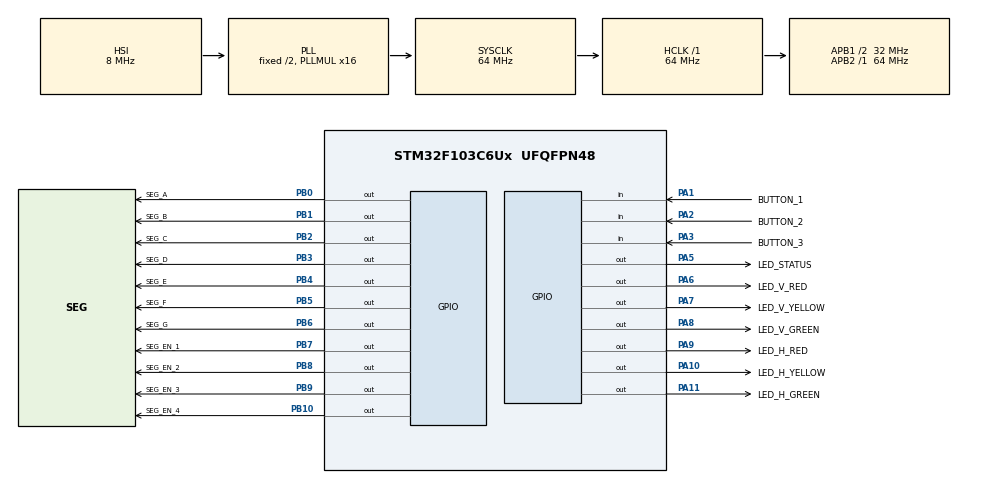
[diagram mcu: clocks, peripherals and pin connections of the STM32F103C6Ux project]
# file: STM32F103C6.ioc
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Mcu.Family=STM32F1
Mcu.Name=STM32F103C6Ux
Mcu.Package=UFQFPN48
NVIC.PriorityGroup=NVIC_PRIORITYGROUP_4
NVIC.TIM2_IRQn=true\:0\:0\:false\:false\:true\:true\:true\:true
PA1.GPIO_Label=BUTTON_1
PA1.GPIO_PuPd=GPIO_PULLUP
PA1.Signal=GPIO_Input
PA10.GPIO_Label=LED_H_YELLOW
PA10.Signal=GPIO_Output
PA11.GPIO_Label=LED_H_GREEN
PA11.Signal=GPIO_Output
PA2.GPIO_Label=BUTTON_2
PA2.GPIO_PuPd=GPIO_PULLUP
PA2.Signal=GPIO_Input
PA3.GPIO_Label=BUTTON_3
PA3.GPIO_PuPd=GPIO_PULLUP
PA3.Signal=GPIO_Input
PA5.GPIO_Label=LED_STATUS
PA5.Signal=GPIO_Output
PA6.GPIO_Label=LED_V_RED
PA6.Signal=GPIO_Output
PA7.GPIO_Label=LED_V_YELLOW
PA7.Signal=GPIO_Output
PA8.GPIO_Label=LED_V_GREEN
PA8.Signal=GPIO_Output
PA9.GPIO_Label=LED_H_RED
PA9.Signal=GPIO_Output
PB0.GPIO_Label=SEG_A
PB0.Signal=GPIO_Output
PB1.GPIO_Label=SEG_B
PB1.Signal=GPIO_Output
PB10.GPIO_Label=SEG_EN_4
PB10.Signal=GPIO_Output
PB2.GPIO_Label=SEG_C
PB2.Signal=GPIO_Output
PB3.GPIO_Label=SEG_D
PB3.Signal=GPIO_Output
PB4.GPIO_Label=SEG_E
PB4.Signal=GPIO_Output
PB5.GPIO_Label=SEG_F
PB5.Signal=GPIO_Output
PB6.GPIO_Label=SEG_G
PB6.Signal=GPIO_Output
PB7.GPIO_Label=SEG_EN_1
PB7.Signal=GPIO_Output
PB8.GPIO_Label=SEG_EN_2
PB8.Signal=GPIO_Output
PB9.GPIO_Label=SEG_EN_3
PB9.Signal=GPIO_Output
ProjectManager.HeapSize=0x200
ProjectManager.StackSize=0x400
ProjectManager.TargetToolchain=Makefile
RCC.AHBFreq_Value=64000000
RCC.APB1CLKDivider=RCC_HCLK_DIV2
RCC.APB1Freq_Value=32000000
RCC.APB1TimFreq_Value=64000000
RCC.APB2Freq_Value=64000000
RCC.APB2TimFreq_Value=64000000
RCC.HCLKFreq_Value=64000000
RCC.PLLMUL=RCC_PLL_MUL16
RCC.SYSCLKFreq_VALUE=64000000
RCC.SYSCLKSource=RCC_SYSCLKSOURCE_PLLCLK
RCC.USBFreq_Value=64000000
TIM2.Period=9
TIM2.Prescaler=6399
VP_SYS_VS_ND.Mode=No_Debug
VP_TIM2_VS_ClockSourceINT.Mode=Internal
board=custom

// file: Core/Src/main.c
/* USER CODE BEGIN Header */
/**
 ******************************************************************************
 * @file           : main.c
 * @brief          : Main program body
 ******************************************************************************
 * @attention
 *
 * Copyright (c) 2023 STMicroelectronics.
 * All rights reserved.
 *
 * This software is licensed under terms that can be found in the LICENSE file
 * in the root directory of this software component.
 * If no LICENSE file comes with this software, it is provided AS-IS.
 *
 ******************************************************************************
 */
/* USER CODE END Header */
#include "main.h"
#include "tim.h"
#include "gpio.h"

/* USER CODE BEGIN Includes */
#include "traffic_sim.h"
/* USER CODE END Includes */

void SystemClock_Config(void);

int main(void)
{

  /* MCU Configuration--------------------------------------------------------*/

  /* Reset of all peripherals, Initializes the Flash interface and the Systick. */
  HAL_Init();

  /* Configure the system clock */
  SystemClock_Config();

  /* Initialize all configured peripherals */
  MX_GPIO_Init();
  MX_TIM2_Init();
  /* USER CODE BEGIN 2 */
  traffic_sim_t ts;
  traffic_sim_init(&ts);
  /* USER CODE END 2 */

  /* Infinite loop */
  /* USER CODE BEGIN WHILE */
  while (1) {
    traffic_sim_main(&ts);
    /* USER CODE END WHILE */

  }
}

void SystemClock_Config(void)
{
  RCC_OscInitTypeDef RCC_OscInitStruct = {0};
  RCC_ClkInitTypeDef RCC_ClkInitStruct = {0};

  /** Initializes the RCC Oscillators according to the specified parameters
  * in the RCC_OscInitTypeDef structure.
  */
  RCC_OscInitStruct.OscillatorType = RCC_OSCILLATORTYPE_HSI;
  RCC_OscInitStruct.HSIState = RCC_HSI_ON;
  RCC_OscInitStruct.HSICalibrationValue = RCC_HSICALIBRATION_DEFAULT;
  RCC_OscInitStruct.PLL.PLLState = RCC_PLL_ON;
  RCC_OscInitStruct.PLL.PLLSource = RCC_PLLSOURCE_HSI_DIV2;
  RCC_OscInitStruct.PLL.PLLMUL = RCC_PLL_MUL16;
  if (HAL_RCC_OscConfig(&RCC_OscInitStruct) != HAL_OK)
  {
    Error_Handler();
  }

  /** Initializes the CPU, AHB and APB buses clocks
  */
  RCC_ClkInitStruct.ClockType = RCC_CLOCKTYPE_HCLK|RCC_CLOCKTYPE_SYSCLK
                              |RCC_CLOCKTYPE_PCLK1|RCC_CLOCKTYPE_PCLK2;
  RCC_ClkInitStruct.SYSCLKSource = RCC_SYSCLKSOURCE_PLLCLK;
  RCC_ClkInitStruct.AHBCLKDivider = RCC_SYSCLK_DIV1;
  RCC_ClkInitStruct.APB1CLKDivider = RCC_HCLK_DIV2;
  RCC_ClkInitStruct.APB2CLKDivider = RCC_HCLK_DIV1;

  if (HAL_RCC_ClockConfig(&RCC_ClkInitStruct, FLASH_LATENCY_2) != HAL_OK)
  {
    Error_Handler();
  }
}

void Error_Handler(void)
{
  __disable_irq();
  while (1) {
  }
}

#ifdef  USE_FULL_ASSERT
/**
  * @brief  Reports the name of the source file and the source line number
  *         where the assert_param error has occurred.
  * @param  file: pointer to the source file name
  * @param  line: assert_param error line source number
  * @retval None
  */
void assert_failed(uint8_t *file, uint32_t line)
{
  /* USER CODE BEGIN 6 */
  /* User can add his own implementation to report the file name and line
number, ex: printf("Wrong parameters value: file %s on line %d\r\n", file, line)
*/
  /* USER CODE END 6 */
}
#endif /* USE_FULL_ASSERT */
